AUTOSAR XML (schema 314)
package /ComponentType
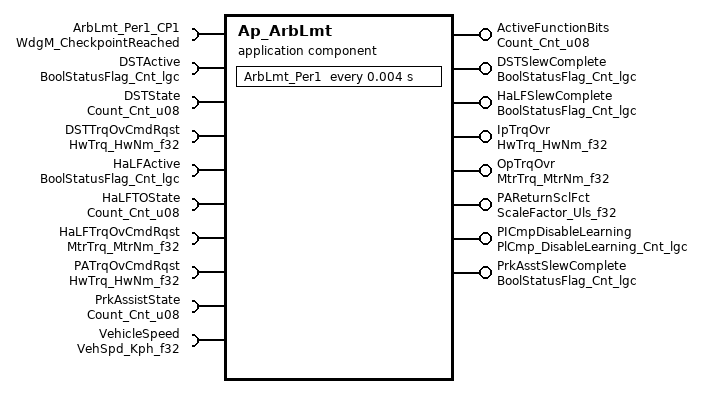
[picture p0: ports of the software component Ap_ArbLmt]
  application software component type Ap_ArbLmt
    8 x provide port:
      ActiveFunctionBits: unqueued-sender-com-spec{data-element=Cnt_u08, can-invalidate=false, init-value=D_ZERO_CNT_U8}, provided-interface=Count_Cnt_u08
      DSTSlewComplete: unqueued-sender-com-spec{data-element=Cnt_lgc, can-invalidate=false, init-value=D_FALSE_CNT_LGC}, provided-interface=BoolStatusFlag_Cnt_lgc
      HaLFSlewComplete: unqueued-sender-com-spec{data-element=Cnt_lgc, can-invalidate=false, init-value=D_FALSE_CNT_LGC}, provided-interface=BoolStatusFlag_Cnt_lgc
      IpTrqOvr: unqueued-sender-com-spec{data-element=HwNm_f32, can-invalidate=false, init-value=D_ZERO_ULS_F32}, provided-interface=HwTrq_HwNm_f32
      OpTrqOvr: unqueued-sender-com-spec{data-element=MtrNm_f32, can-invalidate=false, init-value=D_ZERO_ULS_F32}, provided-interface=MtrTrq_MtrNm_f32
      PAReturnSclFct: unqueued-sender-com-spec{data-element=Uls_f32, can-invalidate=false, init-value=D_ONE_ULS_F32}, provided-interface=ScaleFactor_Uls_f32
      PICmpDisableLearning: unqueued-sender-com-spec{data-element=Cnt_lgc, can-invalidate=false, init-value=D_FALSE_CNT_LGC}, provided-interface=PlCmp_DisableLearning_Cnt_lgc
      PrkAsstSlewComplete: unqueued-sender-com-spec{data-element=Cnt_lgc, can-invalidate=false, init-value=D_FALSE_CNT_LGC}, provided-interface=BoolStatusFlag_Cnt_lgc
    10 x require port:
      ArbLmt_Per1_CP1: client-com-spec=CheckpointReached, required-interface=WdgM_CheckpointReached
      DSTActive: unqueued-receiver-com-spec{data-element=Cnt_lgc, init-value=D_FALSE_CNT_LGC}, required-interface=BoolStatusFlag_Cnt_lgc
      DSTState: unqueued-receiver-com-spec{data-element=Cnt_u08, init-value=D_ZERO_CNT_U8}, required-interface=Count_Cnt_u08
      DSTTrqOvCmdRqst: unqueued-receiver-com-spec{data-element=HwNm_f32, init-value=D_ZERO_ULS_F32}, required-interface=HwTrq_HwNm_f32
      HaLFActive: unqueued-receiver-com-spec{data-element=Cnt_lgc, init-value=D_FALSE_CNT_LGC}, required-interface=BoolStatusFlag_Cnt_lgc
      HaLFTOState: unqueued-receiver-com-spec{data-element=Cnt_u08, init-value=D_ZERO_CNT_U8}, required-interface=Count_Cnt_u08
      HaLFTrqOvCmdRqst: unqueued-receiver-com-spec{data-element=MtrNm_f32, init-value=D_ZERO_ULS_F32}, required-interface=MtrTrq_MtrNm_f32
      PATrqOvCmdRqst: unqueued-receiver-com-spec{data-element=HwNm_f32, init-value=D_ZERO_ULS_F32}, required-interface=HwTrq_HwNm_f32
      PrkAssistState: unqueued-receiver-com-spec{data-element=Cnt_u08, init-value=D_ZERO_CNT_U8}, required-interface=Count_Cnt_u08
      VehicleSpeed: unqueued-receiver-com-spec{data-element=Kph_f32, init-value=D_ZERO_ULS_F32}, required-interface=VehSpd_Kph_f32
  internal behavior Ap_ArbLmt_InternalBehavior: component=Ap_ArbLmt
    timing event TMT_ArbLmt_Per1: start-on-event=ArbLmt_Per1, period=0.004
    port-api-options:
      enable-take-address=false, indirect-api=false, port=ActiveFunctionBits
      enable-take-address=false, indirect-api=false, port=ArbLmt_Per1_CP1
      enable-take-address=false, indirect-api=false, port=DSTActive
      enable-take-address=false, indirect-api=false, port=DSTSlewComplete
      enable-take-address=false, indirect-api=false, port=DSTState
      enable-take-address=false, indirect-api=false, port=DSTTrqOvCmdRqst
      enable-take-address=false, indirect-api=false, port=HaLFActive
      enable-take-address=false, indirect-api=false, port=HaLFSlewComplete
      enable-take-address=false, indirect-api=false, port=HaLFTOState
      enable-take-address=false, indirect-api=false, port=HaLFTrqOvCmdRqst
      enable-take-address=false, indirect-api=false, port=IpTrqOvr
      enable-take-address=false, indirect-api=false, port=OpTrqOvr
      enable-take-address=false, indirect-api=false, port=PAReturnSclFct
      enable-take-address=false, indirect-api=false, port=PATrqOvCmdRqst
      enable-take-address=false, indirect-api=false, port=PICmpDisableLearning
      enable-take-address=false, indirect-api=false, port=PrkAssistState
      enable-take-address=false, indirect-api=false, port=PrkAsstSlewComplete
      enable-take-address=false, indirect-api=false, port=VehicleSpeed
    runnable ArbLmt_Per1
      9 x data read access:
        READ_DSTActive_Cnt_lgc: data-element=DSTActive.Cnt_lgc
        READ_DSTState_Cnt_u08: data-element=DSTState.Cnt_u08
        READ_DSTTrqOvCmdRqst_HwNm_f32: data-element=DSTTrqOvCmdRqst.HwNm_f32
        READ_HaLFActive_Cnt_lgc: data-element=HaLFActive.Cnt_lgc
        READ_HaLFTOState_Cnt_u08: data-element=HaLFTOState.Cnt_u08
        READ_HaLFTrqOvCmdRqst_MtrNm_f32: data-element=HaLFTrqOvCmdRqst.MtrNm_f32
        READ_PATrqOvCmdRqst_HwNm_f32: data-element=PATrqOvCmdRqst.HwNm_f32
        READ_PrkAssistState_Cnt_u08: data-element=PrkAssistState.Cnt_u08
        READ_VehicleSpeed_Kph_f32: data-element=VehicleSpeed.Kph_f32
      8 x data write access:
        WRITE_ActiveFunctionBits_Cnt_u08: data-element=ActiveFunctionBits.Cnt_u08
        WRITE_DSTSlewComplete_Cnt_lgc: data-element=DSTSlewComplete.Cnt_lgc
        WRITE_HaLFSlewComplete_Cnt_lgc: data-element=HaLFSlewComplete.Cnt_lgc
        WRITE_IpTrqOvr_HwNm_f32: data-element=IpTrqOvr.HwNm_f32
        WRITE_OpTrqOvr_MtrNm_f32: data-element=OpTrqOvr.MtrNm_f32
        WRITE_PAReturnSclFct_Uls_f32: data-element=PAReturnSclFct.Uls_f32
        WRITE_PICmpDisableLearning_Cnt_lgc: data-element=PICmpDisableLearning.Cnt_lgc
        WRITE_PrkAsstSlewComplete_Cnt_lgc: data-element=PrkAsstSlewComplete.Cnt_lgc
      sync call SC_ArbLmt_Per1_CP1_CheckpointReached: operation=ArbLmt_Per1_CP1.CheckpointReached, timeout=0
  swc implementation Ap_ArbLmt_Implementation: behavior=Ap_ArbLmt_InternalBehavior
    code-descriptors:
      code Code: type=SRC
